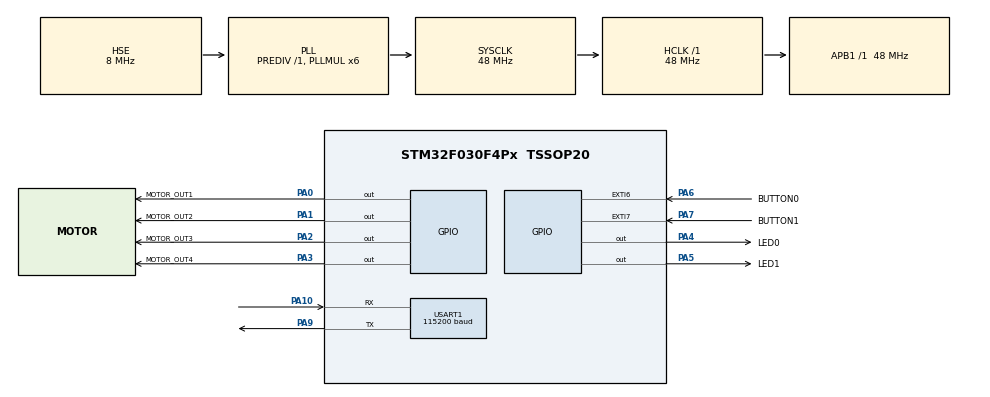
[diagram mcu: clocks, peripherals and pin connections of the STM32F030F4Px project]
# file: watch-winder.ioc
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Mcu.Family=STM32F0
Mcu.Name=STM32F030F4Px
Mcu.Package=TSSOP20
NVIC.EXTI4_15_IRQn=true\:3\:0\:true\:false\:true\:true\:true\:true
NVIC.RTC_IRQn=true\:3\:0\:true\:false\:true\:true\:true\:true
NVIC.TIM14_IRQn=true\:1\:0\:true\:false\:true\:true\:true\:true
PA0.GPIO_Label=MOTOR_OUT1
PA0.Signal=GPIO_Output
PA1.GPIO_Label=MOTOR_OUT2
PA1.Signal=GPIO_Output
PA10.Mode=Asynchronous
PA10.Signal=USART1_RX
PA13.Mode=Serial_Wire
PA13.Signal=SYS_SWDIO
PA14.Mode=Serial_Wire
PA14.Signal=SYS_SWCLK
PA2.GPIO_Label=MOTOR_OUT3
PA2.Signal=GPIO_Output
PA3.GPIO_Label=MOTOR_OUT4
PA3.Signal=GPIO_Output
PA4.GPIO_Label=LED0
PA4.Signal=GPIO_Output
PA5.GPIO_Label=LED1
PA5.Signal=GPIO_Output
PA6.GPIO_Label=BUTTON0
PA6.GPIO_ModeDefaultEXTI=GPIO_MODE_IT_FALLING
PA6.GPIO_PuPd=GPIO_PULLUP
PA6.Signal=GPXTI6
PA7.GPIO_Label=BUTTON1
PA7.GPIO_ModeDefaultEXTI=GPIO_MODE_IT_FALLING
PA7.GPIO_PuPd=GPIO_PULLUP
PA7.Signal=GPXTI7
PA9.Mode=Asynchronous
PA9.Signal=USART1_TX
PF0-OSC_IN.Mode=HSE-External-Oscillator
PF0-OSC_IN.Signal=RCC_OSC_IN
PF1-OSC_OUT.Mode=HSE-External-Oscillator
PF1-OSC_OUT.Signal=RCC_OSC_OUT
ProjectManager.HeapSize=0x200
ProjectManager.StackSize=0x400
ProjectManager.TargetToolchain=STM32CubeIDE
RCC.AHBFreq_Value=48000000
RCC.APB1Freq_Value=48000000
RCC.APB1TimFreq_Value=48000000
RCC.EnbaleCSS=true
RCC.HCLKFreq_Value=48000000
RCC.PLLMUL=RCC_PLL_MUL6
RCC.PLLSourceVirtual=RCC_PLLSOURCE_HSE
RCC.RTCClockSelection=RCC_RTCCLKSOURCE_HSE_DIV32
RCC.SYSCLKFreq_VALUE=48000000
RCC.SYSCLKSource=RCC_SYSCLKSOURCE_PLLCLK
RTC.Alarm=RTC_ALARM_A
RTC.AsynchPrediv=124
RTC.HourFormat=RTC_HOURFORMAT_24
RTC.SynchPrediv=1999
TIM14.Channel=TIM_CHANNEL_1
TIM14.Prescaler=47
USART1.BaudRate=115200
USART1.OverrunDisableParam=ADVFEATURE_OVERRUN_ENABLE
USART1.VirtualMode-Asynchronous=VM_ASYNC
VP_RTC_VS_RTC_Activate.Mode=RTC_Enabled
VP_RTC_VS_RTC_Alarm_A_Intern.Mode=Alarm A
VP_RTC_VS_RTC_Calendar.Mode=RTC_Calendar
VP_TIM14_VS_ClockSourceINT.Mode=Enable_Timer
VP_TIM14_VS_no_output1.Mode=Output Compare1 No Output
board=custom

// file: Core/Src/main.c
/* USER CODE BEGIN Header */
/**
  ******************************************************************************
  * @file           : main.c
  * @brief          : Main program body
  ******************************************************************************
  * @attention
  *
  * Copyright (c) 2023 STMicroelectronics.
  * All rights reserved.
  *
  * This software is licensed under terms that can be found in the LICENSE file
  * in the root directory of this software component.
  * If no LICENSE file comes with this software, it is provided AS-IS.
  *
  ******************************************************************************
  */
/* USER CODE END Header */
#include "main.h"

/* USER CODE BEGIN Includes */
#include "program.h"

/* USER CODE END Includes */

RTC_HandleTypeDef hrtc;

TIM_HandleTypeDef htim14;

UART_HandleTypeDef huart1;

void SystemClock_Config(void);
static void MX_GPIO_Init(void);
static void MX_USART1_UART_Init(void);
static void MX_TIM14_Init(void);
static void MX_RTC_Init(void);

int main(void)
{

  /* MCU Configuration--------------------------------------------------------*/

  /* Reset of all peripherals, Initializes the Flash interface and the Systick. */
  HAL_Init();

  /* Configure the system clock */
  SystemClock_Config();

  /* Initialize all configured peripherals */
  MX_GPIO_Init();
  MX_USART1_UART_Init();
  MX_TIM14_Init();
  MX_RTC_Init();
  /* USER CODE BEGIN 2 */
  Program_Init();

  /* USER CODE END 2 */

  /* Infinite loop */
  /* USER CODE BEGIN WHILE */
  while (1)
  {
	Program_Loop();
    /* USER CODE END WHILE */

  }
}

void SystemClock_Config(void)
{
  RCC_OscInitTypeDef RCC_OscInitStruct = {0};
  RCC_ClkInitTypeDef RCC_ClkInitStruct = {0};
  RCC_PeriphCLKInitTypeDef PeriphClkInit = {0};

  /** Initializes the RCC Oscillators according to the specified parameters
  * in the RCC_OscInitTypeDef structure.
  */
  RCC_OscInitStruct.OscillatorType = RCC_OSCILLATORTYPE_HSE;
  RCC_OscInitStruct.HSEState = RCC_HSE_ON;
  RCC_OscInitStruct.PLL.PLLState = RCC_PLL_ON;
  RCC_OscInitStruct.PLL.PLLSource = RCC_PLLSOURCE_HSE;
  RCC_OscInitStruct.PLL.PLLMUL = RCC_PLL_MUL6;
  RCC_OscInitStruct.PLL.PREDIV = RCC_PREDIV_DIV1;
  if (HAL_RCC_OscConfig(&RCC_OscInitStruct) != HAL_OK)
  {
    Error_Handler();
  }

  /** Initializes the CPU, AHB and APB buses clocks
  */
  RCC_ClkInitStruct.ClockType = RCC_CLOCKTYPE_HCLK|RCC_CLOCKTYPE_SYSCLK
                              |RCC_CLOCKTYPE_PCLK1;
  RCC_ClkInitStruct.SYSCLKSource = RCC_SYSCLKSOURCE_PLLCLK;
  RCC_ClkInitStruct.AHBCLKDivider = RCC_SYSCLK_DIV1;
  RCC_ClkInitStruct.APB1CLKDivider = RCC_HCLK_DIV1;

  if (HAL_RCC_ClockConfig(&RCC_ClkInitStruct, FLASH_LATENCY_1) != HAL_OK)
  {
    Error_Handler();
  }
  PeriphClkInit.PeriphClockSelection = RCC_PERIPHCLK_USART1|RCC_PERIPHCLK_RTC;
  PeriphClkInit.Usart1ClockSelection = RCC_USART1CLKSOURCE_PCLK1;
  PeriphClkInit.RTCClockSelection = RCC_RTCCLKSOURCE_HSE_DIV32;
  if (HAL_RCCEx_PeriphCLKConfig(&PeriphClkInit) != HAL_OK)
  {
    Error_Handler();
  }

  /** Enables the Clock Security System
  */
  HAL_RCC_EnableCSS();
}

static void MX_RTC_Init(void)
{

  RTC_TimeTypeDef sTime = {0};
  RTC_DateTypeDef sDate = {0};
  RTC_AlarmTypeDef sAlarm = {0};

  /** Initialize RTC Only
  */
  hrtc.Instance = RTC;
  hrtc.Init.HourFormat = RTC_HOURFORMAT_24;
  hrtc.Init.AsynchPrediv = 124;
  hrtc.Init.SynchPrediv = 1999;
  hrtc.Init.OutPut = RTC_OUTPUT_DISABLE;
  hrtc.Init.OutPutPolarity = RTC_OUTPUT_POLARITY_HIGH;
  hrtc.Init.OutPutType = RTC_OUTPUT_TYPE_OPENDRAIN;
  if (HAL_RTC_Init(&hrtc) != HAL_OK)
  {
    Error_Handler();
  }

  /** Initialize RTC and set the Time and Date
  */
  sTime.Hours = 0x0;
  sTime.Minutes = 0x0;
  sTime.Seconds = 0x0;
  sTime.DayLightSaving = RTC_DAYLIGHTSAVING_NONE;
  sTime.StoreOperation = RTC_STOREOPERATION_RESET;
  if (HAL_RTC_SetTime(&hrtc, &sTime, RTC_FORMAT_BCD) != HAL_OK)
  {
    Error_Handler();
  }
  sDate.WeekDay = RTC_WEEKDAY_MONDAY;
  sDate.Month = RTC_MONTH_JANUARY;
  sDate.Date = 0x1;
  sDate.Year = 0x0;

  if (HAL_RTC_SetDate(&hrtc, &sDate, RTC_FORMAT_BCD) != HAL_OK)
  {
    Error_Handler();
  }

  /** Enable the Alarm A
  */
  sAlarm.AlarmTime.Hours = 0x0;
  sAlarm.AlarmTime.Minutes = 0x0;
  sAlarm.AlarmTime.Seconds = 0x0;
  sAlarm.AlarmTime.SubSeconds = 0x0;
  sAlarm.AlarmTime.DayLightSaving = RTC_DAYLIGHTSAVING_NONE;
  sAlarm.AlarmTime.StoreOperation = RTC_STOREOPERATION_RESET;
  sAlarm.AlarmMask = RTC_ALARMMASK_NONE;
  sAlarm.AlarmSubSecondMask = RTC_ALARMSUBSECONDMASK_ALL;
  sAlarm.AlarmDateWeekDaySel = RTC_ALARMDATEWEEKDAYSEL_DATE;
  sAlarm.AlarmDateWeekDay = 0x1;
  sAlarm.Alarm = RTC_ALARM_A;
  if (HAL_RTC_SetAlarm_IT(&hrtc, &sAlarm, RTC_FORMAT_BCD) != HAL_OK)
  {
    Error_Handler();
  }

}

static void MX_TIM14_Init(void)
{

  TIM_OC_InitTypeDef sConfigOC = {0};

  htim14.Instance = TIM14;
  htim14.Init.Prescaler = 47;
  htim14.Init.CounterMode = TIM_COUNTERMODE_UP;
  htim14.Init.Period = 65535;
  htim14.Init.ClockDivision = TIM_CLOCKDIVISION_DIV1;
  htim14.Init.AutoReloadPreload = TIM_AUTORELOAD_PRELOAD_DISABLE;
  if (HAL_TIM_Base_Init(&htim14) != HAL_OK)
  {
    Error_Handler();
  }
  if (HAL_TIM_OC_Init(&htim14) != HAL_OK)
  {
    Error_Handler();
  }
  sConfigOC.OCMode = TIM_OCMODE_TIMING;
  sConfigOC.Pulse = 0;
  sConfigOC.OCPolarity = TIM_OCPOLARITY_HIGH;
  sConfigOC.OCFastMode = TIM_OCFAST_DISABLE;
  if (HAL_TIM_OC_ConfigChannel(&htim14, &sConfigOC, TIM_CHANNEL_1) != HAL_OK)
  {
    Error_Handler();
  }

}

static void MX_USART1_UART_Init(void)
{

  huart1.Instance = USART1;
  huart1.Init.BaudRate = 115200;
  huart1.Init.WordLength = UART_WORDLENGTH_8B;
  huart1.Init.StopBits = UART_STOPBITS_1;
  huart1.Init.Parity = UART_PARITY_NONE;
  huart1.Init.Mode = UART_MODE_TX_RX;
  huart1.Init.HwFlowCtl = UART_HWCONTROL_NONE;
  huart1.Init.OverSampling = UART_OVERSAMPLING_16;
  huart1.Init.OneBitSampling = UART_ONE_BIT_SAMPLE_DISABLE;
  huart1.AdvancedInit.AdvFeatureInit = UART_ADVFEATURE_NO_INIT;
  if (HAL_UART_Init(&huart1) != HAL_OK)
  {
    Error_Handler();
  }

}

static void MX_GPIO_Init(void)
{
  GPIO_InitTypeDef GPIO_InitStruct = {0};

  /* GPIO Ports Clock Enable */
  __HAL_RCC_GPIOF_CLK_ENABLE();
  __HAL_RCC_GPIOA_CLK_ENABLE();

  /*Configure GPIO pin Output Level */
  HAL_GPIO_WritePin(GPIOA, MOTOR_OUT1_Pin|MOTOR_OUT2_Pin|MOTOR_OUT3_Pin|MOTOR_OUT4_Pin
                          |LED0_Pin|LED1_Pin, GPIO_PIN_RESET);

  /*Configure GPIO pins : MOTOR_OUT1_Pin MOTOR_OUT2_Pin MOTOR_OUT3_Pin MOTOR_OUT4_Pin
                           LED0_Pin LED1_Pin */
  GPIO_InitStruct.Pin = MOTOR_OUT1_Pin|MOTOR_OUT2_Pin|MOTOR_OUT3_Pin|MOTOR_OUT4_Pin
                          |LED0_Pin|LED1_Pin;
  GPIO_InitStruct.Mode = GPIO_MODE_OUTPUT_PP;
  GPIO_InitStruct.Pull = GPIO_NOPULL;
  GPIO_InitStruct.Speed = GPIO_SPEED_FREQ_LOW;
  HAL_GPIO_Init(GPIOA, &GPIO_InitStruct);

  /*Configure GPIO pins : BUTTON0_Pin BUTTON1_Pin */
  GPIO_InitStruct.Pin = BUTTON0_Pin|BUTTON1_Pin;
  GPIO_InitStruct.Mode = GPIO_MODE_IT_FALLING;
  GPIO_InitStruct.Pull = GPIO_PULLUP;
  HAL_GPIO_Init(GPIOA, &GPIO_InitStruct);

  /* EXTI interrupt init*/
  HAL_NVIC_SetPriority(EXTI4_15_IRQn, 3, 0);
  HAL_NVIC_EnableIRQ(EXTI4_15_IRQn);

}

void Error_Handler(void)
{
  __disable_irq();
  while (1)
  {
  }
}
